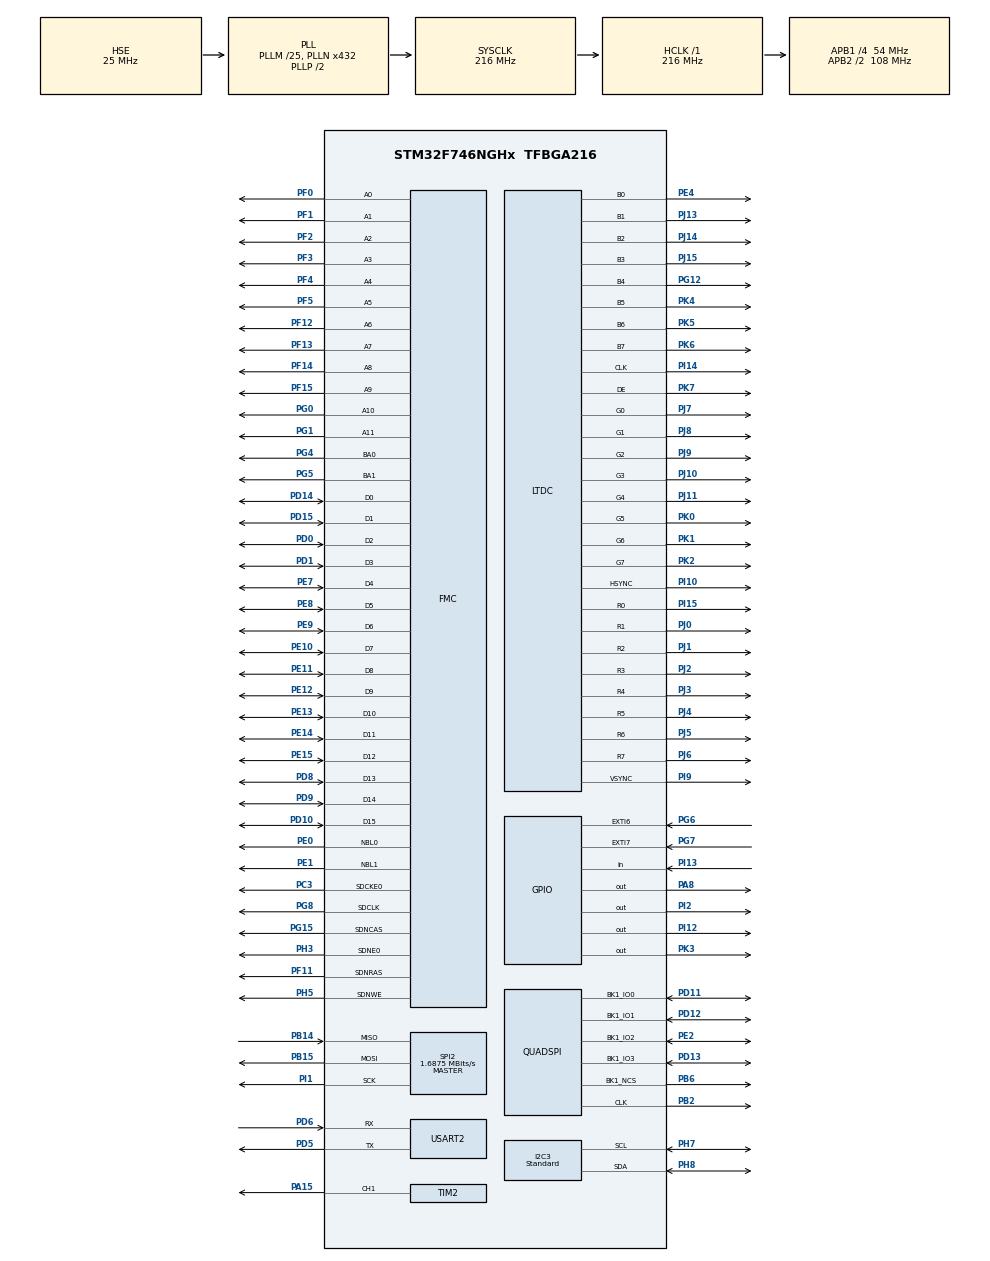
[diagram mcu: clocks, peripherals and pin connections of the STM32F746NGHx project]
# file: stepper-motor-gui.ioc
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CORTEX_M7.AccessPermission_S-Cortex_Memory_Protection_Unit_Region1_Settings_S=MPU_REGION_FULL_ACCESS
CORTEX_M7.AccessPermission_Spec=MPU_REGION_FULL_ACCESS
CORTEX_M7.BaseAddress_S-Cortex_Memory_Protection_Unit_Region1_Settings_S=0x90000000
CORTEX_M7.BaseAddress_Spec=0x90000000
CORTEX_M7.CPU_DCache=Enabled
CORTEX_M7.CPU_ICache=Enabled
CORTEX_M7.DisableExec_Spec=MPU_INSTRUCTION_ACCESS_ENABLE
CORTEX_M7.Enable_S-Cortex_Memory_Protection_Unit_Region1_Settings_S=MPU_REGION_ENABLE
CORTEX_M7.IsCacheable_S-Cortex_Memory_Protection_Unit_Region1_Settings_S=MPU_ACCESS_CACHEABLE
CORTEX_M7.IsShareable_Spec=MPU_ACCESS_NOT_SHAREABLE
CORTEX_M7.PREFETCH_ENABLE=1
CORTEX_M7.Size_S-Cortex_Memory_Protection_Unit_Region1_Settings_S=MPU_REGION_SIZE_16MB
CORTEX_M7.Size_Spec=MPU_REGION_SIZE_256MB
CORTEX_M7.SubRegionDisable_Spec=0x0
CORTEX_M7.default_mode_Activation=1
FMC.CASLatency1=FMC_SDRAM_CAS_LATENCY_3
FMC.ExitSelfRefreshDelay1=7
FMC.LoadToActiveDelay1=2
FMC.RCDDelay1=2
FMC.RPDelay1=2
FMC.RPDelay2=2
FMC.ReadBurst1=FMC_SDRAM_RBURST_ENABLE
FMC.ReadBurst2=FMC_SDRAM_RBURST_ENABLE
FMC.RowCycleDelay1=7
FMC.RowCycleDelay2=7
FMC.SDClockPeriod1=FMC_SDRAM_CLOCK_PERIOD_2
FMC.SDClockPeriod2=FMC_SDRAM_CLOCK_PERIOD_2
FMC.SelfRefreshTime1=4
FMC.WriteRecoveryTime1=3
I2C3.I2C_Speed_Mode=I2C_Standard
I2C3.Timing=0x20404768
LTDC.ActiveH=272
LTDC.ActiveW=480
LTDC.Alpha_L0=255
LTDC.FBStartAdress_L0=0xC0000000
LTDC.HBP=13
LTDC.HFP=32
LTDC.HSync=41
LTDC.ImageHeight_L0=272
LTDC.ImageWidth_L0=480
LTDC.Layers=0
LTDC.PixelFormat_L0=LTDC_PIXEL_FORMAT_RGB565
LTDC.VSync=10
LTDC.WindowX1_L0=480
LTDC.WindowY1_L0=272
Mcu.Family=STM32F7
Mcu.Name=STM32F746NGHx
Mcu.Package=TFBGA216
NVIC.DMA2D_IRQn=true\:0\:0\:false\:false\:true\:true\:true\:true
NVIC.EXTI9_5_IRQn=true\:0\:0\:false\:false\:true\:true\:true\:true
NVIC.LTDC_IRQn=true\:0\:0\:false\:false\:true\:true\:true\:true
NVIC.PriorityGroup=NVIC_PRIORITYGROUP_4
NVIC.TIM2_IRQn=true\:0\:0\:false\:false\:true\:true\:true\:true
PA13.Mode=Serial_Wire
PA13.Signal=SYS_JTMS-SWDIO
PA14.Mode=Serial_Wire
PA14.Signal=SYS_JTCK-SWCLK
PA15.Signal=S_TIM2_CH1_ETR
PA8.GPIO_Speed=GPIO_SPEED_FREQ_MEDIUM
PA8.PinState=GPIO_PIN_SET
PA8.Signal=GPIO_Output
PB14.Mode=Full_Duplex_Master
PB14.Signal=SPI2_MISO
PB15.Mode=Full_Duplex_Master
PB15.Signal=SPI2_MOSI
PB2.Mode=Single Bank 1
PB2.Signal=QUADSPI_CLK
PB6.Mode=Single Bank 1
PB6.Signal=QUADSPI_BK1_NCS
PC3.Mode=SdramChipSelect1_1
PC3.Signal=FMC_SDCKE0
PD0.Signal=FMC_D2_DA2
PD1.Signal=FMC_D3_DA3
PD10.Signal=FMC_D15_DA15
PD11.Mode=Single Bank 1
PD11.Signal=QUADSPI_BK1_IO0
PD12.Mode=Single Bank 1
PD12.Signal=QUADSPI_BK1_IO1
PD13.Mode=Single Bank 1
PD13.Signal=QUADSPI_BK1_IO3
PD14.Signal=FMC_D0_DA0
PD15.Signal=FMC_D1_DA1
PD5.Mode=Asynchronous
PD5.Signal=USART2_TX
PD6.Mode=Asynchronous
PD6.Signal=USART2_RX
PD8.Signal=FMC_D13_DA13
PD9.Signal=FMC_D14_DA14
PE0.Signal=FMC_NBL0
PE1.Signal=FMC_NBL1
PE10.Signal=FMC_D7_DA7
PE11.Signal=FMC_D8_DA8
PE12.Signal=FMC_D9_DA9
PE13.Signal=FMC_D10_DA10
PE14.Signal=FMC_D11_DA11
PE15.Signal=FMC_D12_DA12
PE2.Mode=Single Bank 1
PE2.Signal=QUADSPI_BK1_IO2
PE4.Mode=RGB888
PE4.Signal=LTDC_B0
PE7.Signal=FMC_D4_DA4
PE8.Signal=FMC_D5_DA5
PE9.Signal=FMC_D6_DA6
PF0.Signal=FMC_A0
PF1.Signal=FMC_A1
PF11.Signal=FMC_SDNRAS
PF12.Signal=FMC_A6
PF13.Signal=FMC_A7
PF14.Signal=FMC_A8
PF15.Signal=FMC_A9
PF2.Signal=FMC_A2
PF3.Signal=FMC_A3
PF4.Signal=FMC_A4
PF5.Signal=FMC_A5
PG0.Signal=FMC_A10
PG1.Signal=FMC_A11
PG12.Mode=RGB888
PG12.Signal=LTDC_B4
PG15.Signal=FMC_SDNCAS
PG4.Signal=FMC_A14_BA0
PG5.Signal=FMC_A15_BA1
PG6.GPIO_ModeDefaultEXTI=GPIO_MODE_IT_RISING_FALLING
PG6.GPIO_PuPd=GPIO_PULLUP
PG6.Signal=GPXTI6
PG7.GPIO_ModeDefaultEXTI=GPIO_MODE_IT_RISING_FALLING
PG7.GPIO_PuPd=GPIO_PULLUP
PG7.Signal=GPXTI7
PG8.Signal=FMC_SDCLK
PH0/OSC_IN.Mode=HSE-External-Oscillator
PH0/OSC_IN.Signal=RCC_OSC_IN
PH1/OSC_OUT.Mode=HSE-External-Oscillator
PH1/OSC_OUT.Signal=RCC_OSC_OUT
PH3.Mode=SdramChipSelect1_1
PH3.Signal=FMC_SDNE0
PH5.Signal=FMC_SDNWE
PH7.Mode=I2C
PH7.Signal=I2C3_SCL
PH8.Mode=I2C
PH8.Signal=I2C3_SDA
PI1.Mode=Full_Duplex_Master
PI1.Signal=SPI2_SCK
PI10.Mode=RGB888
PI10.Signal=LTDC_HSYNC
PI12.Signal=GPIO_Output
PI13.Signal=GPIO_Input
PI14.Mode=RGB888
PI14.Signal=LTDC_CLK
PI15.Mode=RGB888
PI15.Signal=LTDC_R0
PI2.GPIO_Speed=GPIO_SPEED_FREQ_MEDIUM
PI2.Signal=GPIO_Output
PI9.Mode=RGB888
PI9.Signal=LTDC_VSYNC
PJ0.Mode=RGB888
PJ0.Signal=LTDC_R1
PJ1.Mode=RGB888
PJ1.Signal=LTDC_R2
PJ10.Mode=RGB888
PJ10.Signal=LTDC_G3
PJ11.Mode=RGB888
PJ11.Signal=LTDC_G4
PJ13.Mode=RGB888
PJ13.Signal=LTDC_B1
PJ14.Mode=RGB888
PJ14.Signal=LTDC_B2
PJ15.Mode=RGB888
PJ15.Signal=LTDC_B3
PJ2.Mode=RGB888
PJ2.Signal=LTDC_R3
PJ3.Mode=RGB888
PJ3.Signal=LTDC_R4
PJ4.Mode=RGB888
PJ4.Signal=LTDC_R5
PJ5.Mode=RGB888
PJ5.Signal=LTDC_R6
PJ6.Mode=RGB888
PJ6.Signal=LTDC_R7
PJ7.Mode=RGB888
PJ7.Signal=LTDC_G0
PJ8.Mode=RGB888
PJ8.Signal=LTDC_G1
PJ9.Mode=RGB888
PJ9.Signal=LTDC_G2
PK0.Mode=RGB888
PK0.Signal=LTDC_G5
PK1.Mode=RGB888
PK1.Signal=LTDC_G6
PK2.Mode=RGB888
PK2.Signal=LTDC_G7
PK3.Signal=GPIO_Output
PK4.Mode=RGB888
PK4.Signal=LTDC_B5
PK5.Mode=RGB888
PK5.Signal=LTDC_B6
PK6.Mode=RGB888
PK6.Signal=LTDC_B7
PK7.Mode=RGB888
PK7.Signal=LTDC_DE
ProjectManager.HeapSize=0xA00
ProjectManager.StackSize=0xA00
ProjectManager.TargetToolchain=STM32CubeIDE
QUADSPI.ChipSelectHighTime=QSPI_CS_HIGH_TIME_6_CYCLE
QUADSPI.ClockPrescaler=1
QUADSPI.FifoThreshold=4
QUADSPI.FlashSize=24
QUADSPI.SampleShifting=QSPI_SAMPLE_SHIFTING_HALFCYCLE
RCC.AHBFreq_Value=216000000
RCC.APB1CLKDivider=RCC_HCLK_DIV4
RCC.APB1Freq_Value=54000000
RCC.APB1TimFreq_Value=108000000
RCC.APB2CLKDivider=RCC_HCLK_DIV2
RCC.APB2Freq_Value=108000000
RCC.APB2TimFreq_Value=216000000
RCC.CortexFreq_Value=216000000
RCC.HCLKFreq_Value=216000000
RCC.HSE_VALUE=25000000
RCC.HSI_VALUE=16000000
RCC.LSE_VALUE=32768
RCC.PLLM=25
RCC.PLLN=432
RCC.PLLSAIN=384
RCC.PLLSAIR=5
RCC.PLLSAIRDiv=RCC_PLLSAIDIVR_8
RCC.PLLSourceVirtual=RCC_PLLSOURCE_HSE
RCC.SYSCLKFreq_VALUE=216000000
RCC.SYSCLKSource=RCC_SYSCLKSOURCE_PLLCLK
RCC.USBFreq_Value=216000000
RCC.VCOOutputFreq_Value=432000000
SH.FMC_A0.0=FMC_A0,12b-sda1
SH.FMC_A1.0=FMC_A1,12b-sda1
SH.FMC_A10.0=FMC_A10,12b-sda1
SH.FMC_A11.0=FMC_A11,12b-sda1
SH.FMC_A14_BA0.0=FMC_BA0,FourSdramBanks1
SH.FMC_A15_BA1.0=FMC_BA1,FourSdramBanks1
SH.FMC_A2.0=FMC_A2,12b-sda1
SH.FMC_A3.0=FMC_A3,12b-sda1
SH.FMC_A4.0=FMC_A4,12b-sda1
SH.FMC_A5.0=FMC_A5,12b-sda1
SH.FMC_A6.0=FMC_A6,12b-sda1
SH.FMC_A7.0=FMC_A7,12b-sda1
SH.FMC_A8.0=FMC_A8,12b-sda1
SH.FMC_A9.0=FMC_A9,12b-sda1
SH.FMC_D0_DA0.0=FMC_D0,sd-16b-d1
SH.FMC_D10_DA10.0=FMC_D10,sd-16b-d1
SH.FMC_D11_DA11.0=FMC_D11,sd-16b-d1
SH.FMC_D12_DA12.0=FMC_D12,sd-16b-d1
SH.FMC_D13_DA13.0=FMC_D13,sd-16b-d1
SH.FMC_D14_DA14.0=FMC_D14,sd-16b-d1
SH.FMC_D15_DA15.0=FMC_D15,sd-16b-d1
SH.FMC_D1_DA1.0=FMC_D1,sd-16b-d1
SH.FMC_D2_DA2.0=FMC_D2,sd-16b-d1
SH.FMC_D3_DA3.0=FMC_D3,sd-16b-d1
SH.FMC_D4_DA4.0=FMC_D4,sd-16b-d1
SH.FMC_D5_DA5.0=FMC_D5,sd-16b-d1
SH.FMC_D6_DA6.0=FMC_D6,sd-16b-d1
SH.FMC_D7_DA7.0=FMC_D7,sd-16b-d1
SH.FMC_D8_DA8.0=FMC_D8,sd-16b-d1
SH.FMC_D9_DA9.0=FMC_D9,sd-16b-d1
SH.FMC_NBL0.0=FMC_NBL0,Sd2ByteEnable1
SH.FMC_NBL1.0=FMC_NBL1,Sd2ByteEnable1
SH.FMC_SDCLK.0=FMC_SDCLK,12b-sda1
SH.FMC_SDNCAS.0=FMC_SDNCAS,12b-sda1
SH.FMC_SDNRAS.0=FMC_SDNRAS,12b-sda1
SH.FMC_SDNWE.0=FMC_SDNWE,12b-sda1
SH.S_TIM2_CH1_ETR.0=TIM2_CH1,PWM Generation1 CH1
SPI2.BaudRatePrescaler=SPI_BAUDRATEPRESCALER_32
SPI2.CLKPhase=SPI_PHASE_2EDGE
SPI2.CLKPolarity=SPI_POLARITY_HIGH
SPI2.CalculateBaudRate=1.6875 MBits/s
SPI2.DataSize=SPI_DATASIZE_8BIT
SPI2.Direction=SPI_DIRECTION_2LINES
SPI2.Mode=SPI_MODE_MASTER
SPI2.VirtualType=VM_MASTER
STMicroelectronics.X-CUBE-TOUCHGFX.4.24.1.ApplicationCcGraphicsJjApplication=TouchGFXOoGenerator
STMicroelectronics.X-CUBE-TOUCHGFX.4.24.1.tgfx_buffering_strategy=Double
STMicroelectronics.X-CUBE-TOUCHGFX.4.24.1.tgfx_display_interface=disp_ltdc
STMicroelectronics.X-CUBE-TOUCHGFX.4.24.1.tgfx_hardware_accelerator=dma_2d
STMicroelectronics.X-CUBE-TOUCHGFX.4.24.1.tgfx_vsync=vsync_ltdc
STMicroelectronics.X-CUBE-TOUCHGFX.4.24.1_IsPackSelfContextualization=true
TIM2.Channel-PWM\ Generation1\ CH1=TIM_CHANNEL_1
TIM2.Period=0
USART2.VirtualMode-Asynchronous=VM_ASYNC
VP_CRC_VS_CRC.Mode=CRC_Activate
VP_DMA2D_VS_DMA2D.Mode=DMA2D_Activate
VP_STMicroelectronics.X-CUBE-TOUCHGFX_VS_GraphicsJjApplication_4.24.1.Mode=GraphicsJjApplication
VP_TIM2_VS_ClockSourceINT.Mode=Internal
board=custom

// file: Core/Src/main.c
/* USER CODE BEGIN Header */
/**
  ******************************************************************************
  * @file           : main.c
  * @brief          : Main program body
  ******************************************************************************
  * @attention
  *
  * Copyright (c) 2024 STMicroelectronics.
  * All rights reserved.
  *
  * This software is licensed under terms that can be found in the LICENSE file
  * in the root directory of this software component.
  * If no LICENSE file comes with this software, it is provided AS-IS.
  *
  ******************************************************************************
  */
/* USER CODE END Header */
#include "main.h"
#include "crc.h"
#include "dma2d.h"
#include "i2c.h"
#include "ltdc.h"
#include "quadspi.h"
#include "spi.h"
#include "tim.h"
#include "usart.h"
#include "gpio.h"
#include "fmc.h"
#include "app_touchgfx.h"

/* USER CODE BEGIN Includes */
#include "x_nucleo_ihmxx.h"
#include "powerstep01.h"
#include "x_nucleo_ihm03a1_stm32f4xx.h"
#include "stm32746g_discovery_lcd.h"
#include "stm32746g_discovery_ts.h"
#include "stm32746g_discovery.h"
/* USER CODE END Includes */

/* USER CODE BEGIN PV */
static volatile uint16_t gLastError;
uint16_t x;
uint16_t y;
/* USER CODE END PV */

void SystemClock_Config(void);
static void MPU_Config(void);
/* USER CODE BEGIN PFP */
static void MyBusyInterruptHandler(void);
static void MyFlagInterruptHandler(void);
/* USER CODE END PFP */

int main(void)
{

  /* MPU Configuration--------------------------------------------------------*/
  MPU_Config();

  /* Enable the CPU Cache */

  /* Enable I-Cache---------------------------------------------------------*/
  SCB_EnableICache();

  /* Enable D-Cache---------------------------------------------------------*/
  SCB_EnableDCache();

  /* MCU Configuration--------------------------------------------------------*/

  /* Reset of all peripherals, Initializes the Flash interface and the Systick. */
  HAL_Init();

  /* Configure the system clock */
  SystemClock_Config();

  /* Initialize all configured peripherals */
  MX_GPIO_Init();
  MX_SPI2_Init();
  MX_TIM2_Init();
  MX_USART2_UART_Init();
  MX_DMA2D_Init();
  MX_LTDC_Init();
  MX_FMC_Init();
  MX_I2C3_Init();
  MX_CRC_Init();
  MX_QUADSPI_Init();
  MX_TouchGFX_Init();
  /* USER CODE BEGIN 2 */

//  TS_IO_Init();
//
//  uint32_t *externalRAM = 0xC0000000;
//  	const uint32_t size = 1000;
//
//  	//write external RAM
//  	for(int i = 0; i < size; i++)
//  	{
//  	    externalRAM[i] = 0;
//  	}
//
//  	BSP_LCD_Init();
//
//  	    // Select the LCD layer to be used using the BSP_LCD_SelectLayer() function.
//  	    //BSP_LCD_SelectLayer(0);
//  	    BSP_LCD_LayerDefaultInit(LTDC_ACTIVE_LAYER, LCD_FB_START_ADDRESS);
//  	    BSP_LCD_SelectLayer(LTDC_ACTIVE_LAYER);
//
//  	    // Enable the LCD display using the BSP_LCD_DisplayOn() function.
//  	    BSP_LCD_DisplayOn();
//
//  	    // Clear the whole LCD using BSP_LCD_Clear() function or only one specified string line using the BSP_LCD_ClearStringLine() function.
//  	    BSP_LCD_Clear(LCD_COLOR_LIGHTGRAY);
//  	    HAL_Delay(1000);
//
//
//  	    BSP_LCD_Clear(LCD_COLOR_RED);
//  	    HAL_Delay(1000);
//		BSP_LCD_Clear(LCD_COLOR_WHITE);
//
//  	    // Display a character on the specified line and column using the BSP_LCD_DisplayChar() function or a complete string line using the BSP_LCD_DisplayStringAtLine() function.
//  	    BSP_LCD_DisplayStringAt(0, 0, "TEST", CENTER_MODE);

  	//HAL_Delay(2000);

	BSP_MotorControl_SetNbDevices(BSP_MOTOR_CONTROL_BOARD_ID_POWERSTEP01, 1);
	BSP_MotorControl_Init(BSP_MOTOR_CONTROL_BOARD_ID_POWERSTEP01, NULL);
	BSP_MotorControl_AttachFlagInterrupt(MyFlagInterruptHandler);
	BSP_MotorControl_AttachBusyInterrupt(MyBusyInterruptHandler);
	BSP_MotorControl_AttachErrorHandler(Error_Handler);

	//BSP_MotorControl_Move(0, FORWARD, 1600);

	/* Wait for the motor of device 0 ends moving */
	//BSP_MotorControl_WaitWhileActive(0);

	/* Wait for 2 seconds */
	//HAL_Delay(2500);

	//BSP_MotorControl_Move(0, BACKWARD, 1600);

	/* Wait for the motor of device 0 ends moving */
	//BSP_MotorControl_WaitWhileActive(0);

	BSP_MotorControl_CmdSoftHiZ(0);

  /* USER CODE END 2 */

  /* Infinite loop */
  while (1)
  {

  MX_TouchGFX_Process();
    /* USER CODE BEGIN 3 */

//	      TS_StateTypeDef state;
//	      BSP_TS_GetState(&state);
//	      if (state.touchDetected == 1)
//	      {
//	          x = state.touchX[0];
//	          y = state.touchY[0];
//	          //break point here
//	         //BSP_LCD_Clear(LCD_COLOR_WHITE);
//	          BSP_LCD_FillCircle(x, y, 10);
//	      }
//	      HAL_Delay(8);
  }
  /* USER CODE END 3 */
}

void SystemClock_Config(void)
{
  RCC_OscInitTypeDef RCC_OscInitStruct = {0};
  RCC_ClkInitTypeDef RCC_ClkInitStruct = {0};

  /** Configure the main internal regulator output voltage
  */
  __HAL_RCC_PWR_CLK_ENABLE();
  __HAL_PWR_VOLTAGESCALING_CONFIG(PWR_REGULATOR_VOLTAGE_SCALE1);

  /** Initializes the RCC Oscillators according to the specified parameters
  * in the RCC_OscInitTypeDef structure.
  */
  RCC_OscInitStruct.OscillatorType = RCC_OSCILLATORTYPE_HSE;
  RCC_OscInitStruct.HSEState = RCC_HSE_ON;
  RCC_OscInitStruct.PLL.PLLState = RCC_PLL_ON;
  RCC_OscInitStruct.PLL.PLLSource = RCC_PLLSOURCE_HSE;
  RCC_OscInitStruct.PLL.PLLM = 25;
  RCC_OscInitStruct.PLL.PLLN = 432;
  RCC_OscInitStruct.PLL.PLLP = RCC_PLLP_DIV2;
  RCC_OscInitStruct.PLL.PLLQ = 2;
  if (HAL_RCC_OscConfig(&RCC_OscInitStruct) != HAL_OK)
  {
    Error_Handler();
  }

  /** Activate the Over-Drive mode
  */
  if (HAL_PWREx_EnableOverDrive() != HAL_OK)
  {
    Error_Handler();
  }

  /** Initializes the CPU, AHB and APB buses clocks
  */
  RCC_ClkInitStruct.ClockType = RCC_CLOCKTYPE_HCLK|RCC_CLOCKTYPE_SYSCLK
                              |RCC_CLOCKTYPE_PCLK1|RCC_CLOCKTYPE_PCLK2;
  RCC_ClkInitStruct.SYSCLKSource = RCC_SYSCLKSOURCE_PLLCLK;
  RCC_ClkInitStruct.AHBCLKDivider = RCC_SYSCLK_DIV1;
  RCC_ClkInitStruct.APB1CLKDivider = RCC_HCLK_DIV4;
  RCC_ClkInitStruct.APB2CLKDivider = RCC_HCLK_DIV2;

  if (HAL_RCC_ClockConfig(&RCC_ClkInitStruct, FLASH_LATENCY_7) != HAL_OK)
  {
    Error_Handler();
  }
}

/* USER CODE BEGIN 4 */
/**
  * @brief  This function is the User handler for the flag interrupt
  * @param  None
  * @retval None
  */
void MyFlagInterruptHandler(void)
{
  /* Get the value of the status register via the command GET_STATUS */
  uint16_t statusRegister = BSP_MotorControl_CmdGetStatus(0);

  /* Check HIZ flag: if set, power brigdes are disabled */
  if ((statusRegister & POWERSTEP01_STATUS_HIZ) == POWERSTEP01_STATUS_HIZ)
  {
    // HIZ state
  }

  /* Check BUSY flag: if not set, a command is under execution */
  if ((statusRegister & POWERSTEP01_STATUS_BUSY) == 0)
  {
    // BUSY
  }

  /* Check SW_F flag: if not set, the SW input is opened */
  if ((statusRegister & POWERSTEP01_STATUS_SW_F ) == 0)
  {
     // SW OPEN
  }
  else
  {
    // SW CLOSED
  }
  /* Check SW_EN bit */
  if ((statusRegister & POWERSTEP01_STATUS_SW_EVN) == POWERSTEP01_STATUS_SW_EVN)
  {
    // switch turn_on event
  }
  /* Check direction bit */
  if ((statusRegister & POWERSTEP01_STATUS_DIR) == 0)
  {
    // BACKWARD
  }
  else
  {
    // FORWARD
  }
  if ((statusRegister & POWERSTEP01_STATUS_MOT_STATUS) == POWERSTEP01_STATUS_MOT_STATUS_STOPPED )
  {
       // MOTOR STOPPED
  }
  else  if ((statusRegister & POWERSTEP01_STATUS_MOT_STATUS) == POWERSTEP01_STATUS_MOT_STATUS_ACCELERATION )
  {
           // MOTOR ACCELERATION
  }
  else  if ((statusRegister & POWERSTEP01_STATUS_MOT_STATUS) == POWERSTEP01_STATUS_MOT_STATUS_DECELERATION )
  {
           // MOTOR DECELERATION
  }
  else  if ((statusRegister & POWERSTEP01_STATUS_MOT_STATUS) == POWERSTEP01_STATUS_MOT_STATUS_CONST_SPD )
  {
       // MOTOR RUNNING AT CONSTANT SPEED
  }

  /* Check Command Error flag: if set, the command received by SPI can't be */
  /* performed. This occurs for instance when a move command is sent to the */
  /* Powerstep01 while it is already running */
  if ((statusRegister & POWERSTEP01_STATUS_CMD_ERROR) == POWERSTEP01_STATUS_CMD_ERROR)
  {
       // Command Error
  }

  /* Check Step mode clock flag: if set, the device is working in step clock mode */
  if ((statusRegister & POWERSTEP01_STATUS_STCK_MOD) == POWERSTEP01_STATUS_STCK_MOD)
  {
     //Step clock mode enabled
  }

  /* Check UVLO flag: if not set, there is an undervoltage lock-out */
  if ((statusRegister & POWERSTEP01_STATUS_UVLO) == 0)
  {
     //undervoltage lock-out
  }

  /* Check UVLO ADC flag: if not set, there is an ADC undervoltage lock-out */
  if ((statusRegister & POWERSTEP01_STATUS_UVLO_ADC) == 0)
  {
     //ADC undervoltage lock-out
  }

  /* Check thermal STATUS flags: if  set, the thermal status is not normal */
  if ((statusRegister & POWERSTEP01_STATUS_TH_STATUS) != 0)
  {
    //thermal status: 1: Warning, 2: Bridge shutdown, 3: Device shutdown
  }

  /* Check OCD  flag: if not set, there is an overcurrent detection */
  if ((statusRegister & POWERSTEP01_STATUS_OCD) == 0)
  {
    //overcurrent detection
  }

  /* Check STALL_A flag: if not set, there is a Stall condition on bridge A */
  if ((statusRegister & POWERSTEP01_STATUS_STALL_A) == 0)
  {
    //overcurrent detection
  }

  /* Check STALL_B flag: if not set, there is a Stall condition on bridge B */
  if ((statusRegister & POWERSTEP01_STATUS_STALL_B) == 0)
  {
    //overcurrent detection
  }

}

/**
  * @brief  This function is the User handler for the busy interrupt
  * @param  None
  * @retval None
  */
void MyBusyInterruptHandler(void)
{

   if (BSP_MotorControl_CheckBusyHw())
   {
      /* Busy pin is low, so at list one Powerstep01 chip is busy */
     /* To be customized (for example Switch on a LED) */
   }
   else
   {
     /* To be customized (for example Switch off a LED) */
   }
}

/* USER CODE END 4 */

 /* MPU Configuration */

void MPU_Config(void)
{
  MPU_Region_InitTypeDef MPU_InitStruct = {0};

  /* Disables the MPU */
  HAL_MPU_Disable();

  /** Initializes and configures the Region and the memory to be protected
  */
  MPU_InitStruct.Enable = MPU_REGION_ENABLE;
  MPU_InitStruct.Number = MPU_REGION_NUMBER0;
  MPU_InitStruct.BaseAddress = 0x90000000;
  MPU_InitStruct.Size = MPU_REGION_SIZE_256MB;
  MPU_InitStruct.SubRegionDisable = 0x0;
  MPU_InitStruct.TypeExtField = MPU_TEX_LEVEL0;
  MPU_InitStruct.AccessPermission = MPU_REGION_FULL_ACCESS;
  MPU_InitStruct.DisableExec = MPU_INSTRUCTION_ACCESS_ENABLE;
  MPU_InitStruct.IsShareable = MPU_ACCESS_NOT_SHAREABLE;
  MPU_InitStruct.IsCacheable = MPU_ACCESS_NOT_CACHEABLE;
  MPU_InitStruct.IsBufferable = MPU_ACCESS_NOT_BUFFERABLE;

  HAL_MPU_ConfigRegion(&MPU_InitStruct);

  /** Initializes and configures the Region and the memory to be protected
  */
  MPU_InitStruct.Number = MPU_REGION_NUMBER1;
  MPU_InitStruct.Size = MPU_REGION_SIZE_16MB;
  MPU_InitStruct.IsCacheable = MPU_ACCESS_CACHEABLE;

  HAL_MPU_ConfigRegion(&MPU_InitStruct);
  /* Enables the MPU */
  HAL_MPU_Enable(MPU_PRIVILEGED_DEFAULT);

}

void Error_Handler(void)
{
  __disable_irq();
  while (1)
  {
  }
}
